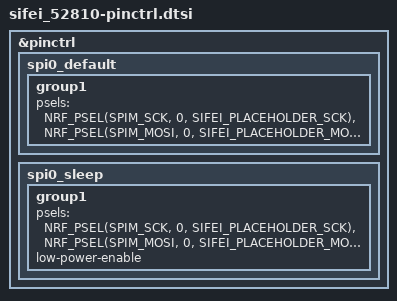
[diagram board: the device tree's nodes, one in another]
/*
 * Copyright (c) 2026 Cremind
 * SPDX-License-Identifier: MIT
 *
 * PLACEHOLDER PINS. The Sifei 52810 display mapping is UNVERIFIED
 * (hardware/matrix.yaml: pins unverified). These numbers are arbitrary: they
 * exist only so memory-fit builds link the SPI and panel drivers. The SPI bus
 * is `zephyr,deferred-init` and the panel is panel-id 255 (UNVERIFIED), so
 * firmware never configures or drives any of them. Replace every
 * SIFEI_PLACEHOLDER_* value with measured pins before setting a real panel-id.
 */

#define SIFEI_PLACEHOLDER_SCK	25
#define SIFEI_PLACEHOLDER_MOSI	23
#define SIFEI_PLACEHOLDER_CS	22
#define SIFEI_PLACEHOLDER_DC	20
#define SIFEI_PLACEHOLDER_RST	19
#define SIFEI_PLACEHOLDER_BUSY	18

&pinctrl {
	spi0_default: spi0_default {
		group1 {
			psels = <NRF_PSEL(SPIM_SCK, 0, SIFEI_PLACEHOLDER_SCK)>,
				<NRF_PSEL(SPIM_MOSI, 0, SIFEI_PLACEHOLDER_MOSI)>;
		};
	};

	spi0_sleep: spi0_sleep {
		group1 {
			psels = <NRF_PSEL(SPIM_SCK, 0, SIFEI_PLACEHOLDER_SCK)>,
				<NRF_PSEL(SPIM_MOSI, 0, SIFEI_PLACEHOLDER_MOSI)>;
			low-power-enable;
		};
	};
};
